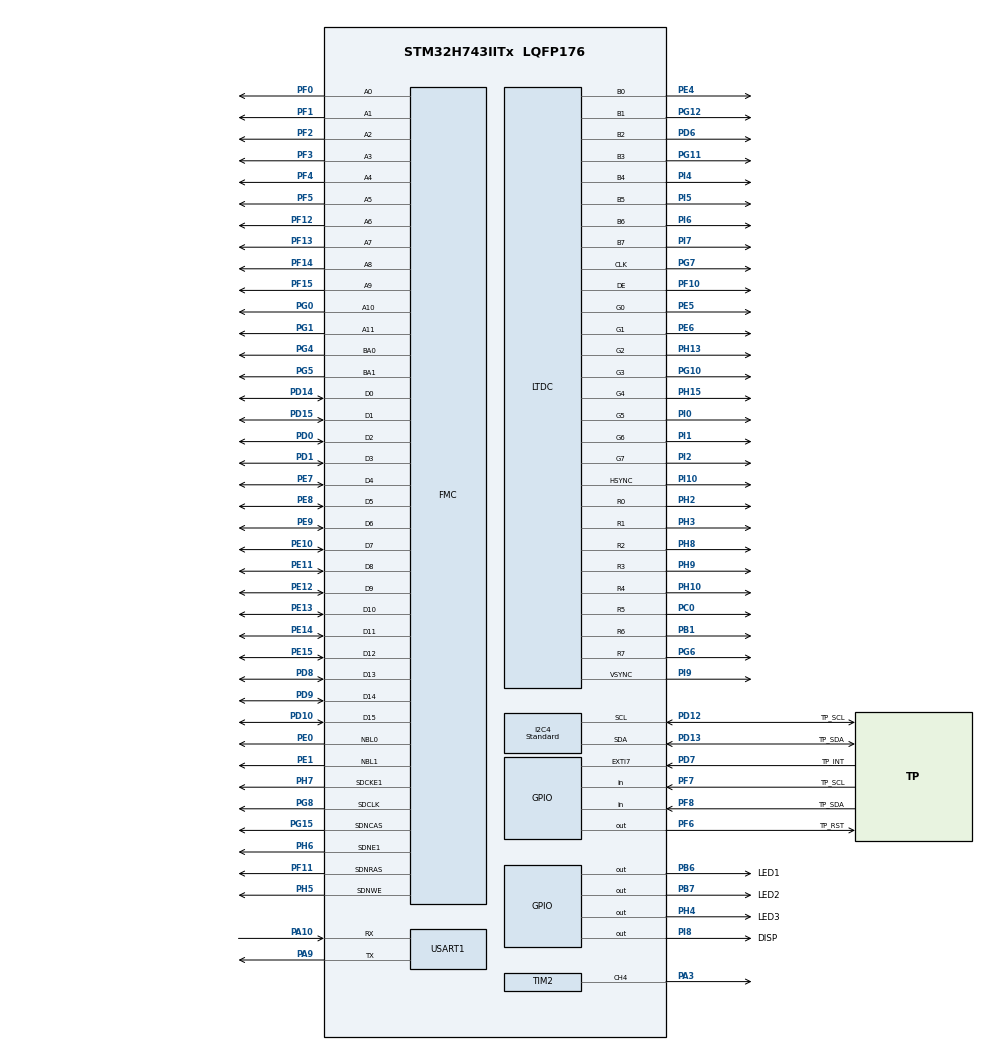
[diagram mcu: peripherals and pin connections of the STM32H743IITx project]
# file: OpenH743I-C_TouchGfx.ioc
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CORTEX_M7.BaseAddress-Cortex_Memory_Protection_Unit_Region0_Settings=0xD0000000
CORTEX_M7.CPU_DCache=Enabled
CORTEX_M7.CPU_ICache=Enabled
CORTEX_M7.Enable-Cortex_Memory_Protection_Unit_Region0_Settings=MPU_REGION_ENABLE
CORTEX_M7.MPU_Control=__NULL
CORTEX_M7.Size-Cortex_Memory_Protection_Unit_Region0_Settings=MPU_REGION_SIZE_16MB
CORTEX_M7.TypeExtField-Cortex_Memory_Protection_Unit_Region0_Settings=MPU_TEX_LEVEL1
DMA2D.ColorMode=DMA2D_OUTPUT_RGB565
FMC.CASLatency1=FMC_SDRAM_CAS_LATENCY_3
FMC.ExitSelfRefreshDelay1=7
FMC.LoadToActiveDelay1=2
FMC.RCDDelay1=2
FMC.RPDelay1=2
FMC.ReadPipeDelay1=FMC_SDRAM_RPIPE_DELAY_1
FMC.RowCycleDelay1=6
FMC.SDClockPeriod1=FMC_SDRAM_CLOCK_PERIOD_2
FMC.SelfRefreshTime1=4
FMC.WriteRecoveryTime1=2
FREERTOS.Tasks01=defaultTask,24,128,StartDefaultTask,Default,NULL,Dynamic,NULL,NULL;TouchGfxTask,24,2048,TouchGFX_Task,As weak,NULL,Dynamic,NULL,NULL
FREERTOS.configUSE_NEWLIB_REENTRANT=1
I2C4.CustomTiming=Disabled
I2C4.DualAddressMode=I2C_DUALADDRESS_DISABLE
I2C4.GeneralCallMode=I2C_GENERALCALL_DISABLE
I2C4.I2C_Speed_Mode=I2C_Standard
I2C4.NoStretchMode=I2C_NOSTRETCH_ENABLE
I2C4.Timing=0x00000E14
LTDC.ActiveW=800
LTDC.Alpha_L0=0xff
LTDC.FBStartAdress_L0=0xD0000000
LTDC.FBStartAdress_L1=0xD0200000
LTDC.HBP=46
LTDC.HFP=6
LTDC.HSync=30
LTDC.ImageHeight_L0=480
LTDC.ImageHeight_L1=480
LTDC.ImageWidth_L0=800
LTDC.Layers=0
LTDC.PixelFormat_L0=LTDC_PIXEL_FORMAT_RGB565
LTDC.VBP=23
LTDC.VFP=22
LTDC.VSync=10
LTDC.WindowX1_L0=800
LTDC.WindowX1_L1=800
LTDC.WindowY1_L0=480
LTDC.WindowY1_L1=480
Mcu.Family=STM32H7
Mcu.Name=STM32H743IITx
Mcu.Package=LQFP176
NVIC.DMA2D_IRQn=true\:5\:0\:false\:false\:true\:true\:true\:true\:true
NVIC.EXTI9_5_IRQn=true\:5\:0\:false\:false\:true\:true\:true\:true\:true
NVIC.LTDC_IRQn=true\:5\:0\:false\:false\:true\:true\:true\:true\:true
NVIC.PriorityGroup=NVIC_PRIORITYGROUP_4
NVIC.TIM1_UP_IRQn=true\:15\:0\:false\:false\:true\:false\:false\:true\:true
NVIC.TimeBase=TIM1_UP_IRQn
NVIC.TimeBaseIP=TIM1
PA10.Mode=Asynchronous
PA10.Signal=USART1_RX
PA3.Signal=S_TIM2_CH4
PA9.Mode=Asynchronous
PA9.Signal=USART1_TX
PB1.GPIO_Speed=GPIO_SPEED_FREQ_LOW
PB1.Mode=RGB888
PB1.Signal=LTDC_R6
PB6.GPIO_Label=LED1
PB6.Signal=GPIO_Output
PB7.GPIO_Label=LED2
PB7.Signal=GPIO_Output
PC0.Mode=RGB888
PC0.Signal=LTDC_R5
PD0.Signal=FMC_D2_DA2
PD1.Signal=FMC_D3_DA3
PD10.Signal=FMC_D15_DA15
PD12.GPIO_Label=TP_SCL
PD12.GPIO_Pu=GPIO_PULLUP
PD12.GPIO_PuPd=GPIO_PULLUP
PD12.GPIO_Speed=GPIO_SPEED_FREQ_HIGH
PD12.Mode=I2C
PD12.Signal=I2C4_SCL
PD13.GPIO_Label=TP_SDA
PD13.GPIO_Pu=GPIO_PULLUP
PD13.GPIO_PuPd=GPIO_PULLUP
PD13.GPIO_Speed=GPIO_SPEED_FREQ_HIGH
PD13.Mode=I2C
PD13.Signal=I2C4_SDA
PD14.Signal=FMC_D0_DA0
PD15.Signal=FMC_D1_DA1
PD6.Mode=RGB888
PD6.Signal=LTDC_B2
PD7.GPIO_Label=TP_INT
PD7.GPIO_PuPd=GPIO_PULLUP
PD7.Signal=GPXTI7
PD8.Signal=FMC_D13_DA13
PD9.Signal=FMC_D14_DA14
PE0.Signal=FMC_NBL0
PE1.Signal=FMC_NBL1
PE10.Signal=FMC_D7_DA7
PE11.Signal=FMC_D8_DA8
PE12.Signal=FMC_D9_DA9
PE13.Signal=FMC_D10_DA10
PE14.Signal=FMC_D11_DA11
PE15.Signal=FMC_D12_DA12
PE4.Mode=RGB888
PE4.Signal=LTDC_B0
PE5.Mode=RGB888
PE5.Signal=LTDC_G0
PE6.Mode=RGB888
PE6.Signal=LTDC_G1
PE7.Signal=FMC_D4_DA4
PE8.Signal=FMC_D5_DA5
PE9.Signal=FMC_D6_DA6
PF0.Signal=FMC_A0
PF1.Signal=FMC_A1
PF10.Mode=RGB888
PF10.Signal=LTDC_DE
PF11.Signal=FMC_SDNRAS
PF12.Signal=FMC_A6
PF13.Signal=FMC_A7
PF14.Signal=FMC_A8
PF15.Signal=FMC_A9
PF2.Signal=FMC_A2
PF3.Signal=FMC_A3
PF4.Signal=FMC_A4
PF5.Signal=FMC_A5
PF6.GPIO_Label=TP_RST
PF6.Signal=GPIO_Output
PF7.GPIO_Label=TP_SCL
PF7.Signal=GPIO_Input
PF8.GPIO_Label=TP_SDA
PF8.GPIO_PuPd=GPIO_PULLUP
PF8.Signal=GPIO_Input
PG0.Signal=FMC_A10
PG1.Signal=FMC_A11
PG10.Mode=RGB888
PG10.Signal=LTDC_G3
PG11.Mode=RGB888
PG11.Signal=LTDC_B3
PG12.Mode=RGB888
PG12.Signal=LTDC_B1
PG15.Signal=FMC_SDNCAS
PG4.Signal=FMC_A14_BA0
PG5.Signal=FMC_A15_BA1
PG6.Mode=RGB888
PG6.Signal=LTDC_R7
PG7.GPIO_Speed=GPIO_SPEED_FREQ_VERY_HIGH
PG7.Mode=RGB888
PG7.Signal=LTDC_CLK
PG8.Signal=FMC_SDCLK
PH0-OSC_IN\ (PH0).Mode=HSE-External-Oscillator
PH0-OSC_IN\ (PH0).Signal=RCC_OSC_IN
PH1-OSC_OUT\ (PH1).Mode=HSE-External-Oscillator
PH1-OSC_OUT\ (PH1).Signal=RCC_OSC_OUT
PH10.Mode=RGB888
PH10.Signal=LTDC_R4
PH13.Mode=RGB888
PH13.Signal=LTDC_G2
PH15.Mode=RGB888
PH15.Signal=LTDC_G4
PH2.Mode=RGB888
PH2.Signal=LTDC_R0
PH3.Mode=RGB888
PH3.Signal=LTDC_R1
PH4.GPIO_Label=LED3
PH4.Signal=GPIO_Output
PH5.Signal=FMC_SDNWE
PH6.Mode=SdramChipSelect2_1
PH6.Signal=FMC_SDNE1
PH7.Mode=SdramChipSelect2_1
PH7.Signal=FMC_SDCKE1
PH8.Mode=RGB888
PH8.Signal=LTDC_R2
PH9.Mode=RGB888
PH9.Signal=LTDC_R3
PI0.Mode=RGB888
PI0.Signal=LTDC_G5
PI1.Mode=RGB888
PI1.Signal=LTDC_G6
PI10.GPIO_Speed=GPIO_SPEED_FREQ_VERY_HIGH
PI10.Mode=RGB888
PI10.Signal=LTDC_HSYNC
PI2.Mode=RGB888
PI2.Signal=LTDC_G7
PI4.Mode=RGB888
PI4.Signal=LTDC_B4
PI5.Mode=RGB888
PI5.Signal=LTDC_B5
PI6.Mode=RGB888
PI6.Signal=LTDC_B6
PI7.Mode=RGB888
PI7.Signal=LTDC_B7
PI8.GPIO_Label=DISP
PI8.PinState=GPIO_PIN_SET
PI8.Signal=GPIO_Output
PI9.GPIO_Speed=GPIO_SPEED_FREQ_VERY_HIGH
PI9.Mode=RGB888
PI9.Signal=LTDC_VSYNC
ProjectManager.HeapSize=0x200
ProjectManager.StackSize=0x400
ProjectManager.TargetToolchain=STM32CubeIDE
RCC.ADCFreq_Value=100000000
RCC.APB1Freq_Value=50000000
RCC.APB2Freq_Value=100000000
RCC.APB3Freq_Value=100000000
RCC.APB4Freq_Value=100000000
RCC.CortexFreq_Value=400000000
RCC.D1PPRE=RCC_APB3_DIV2
RCC.D2PPRE1=RCC_APB1_DIV4
RCC.D2PPRE2=RCC_APB2_DIV2
RCC.D3PPRE=RCC_APB4_DIV2
RCC.DIVM1=4
RCC.DIVM2=4
RCC.DIVM3=4
RCC.DIVN1=400
RCC.DIVN2=100
RCC.DIVN3=96
RCC.DIVQ3=4
RCC.DIVR3=9
RCC.HCLKFreq_Value=200000000
RCC.HPRE=RCC_HCLK_DIV2
RCC.HSE_VALUE=8000000
RCC.I2C4CLockSelection=RCC_I2C4CLKSOURCE_CSI
RCC.PLLSourceVirtual=RCC_PLLSOURCE_HSE
RCC.PWR_Regulator_Voltage_Scale=PWR_REGULATOR_VOLTAGE_SCALE1
RCC.SYSCLKFreq_VALUE=400000000
RCC.SYSCLKSource=RCC_SYSCLKSOURCE_PLLCLK
RCC.USBFreq_Value=400000000
SH.FMC_A0.0=FMC_A0,12b-sda1
SH.FMC_A1.0=FMC_A1,12b-sda1
SH.FMC_A10.0=FMC_A10,12b-sda1
SH.FMC_A11.0=FMC_A11,12b-sda1
SH.FMC_A14_BA0.0=FMC_BA0,FourSdramBanks1
SH.FMC_A15_BA1.0=FMC_BA1,FourSdramBanks1
SH.FMC_A2.0=FMC_A2,12b-sda1
SH.FMC_A3.0=FMC_A3,12b-sda1
SH.FMC_A4.0=FMC_A4,12b-sda1
SH.FMC_A5.0=FMC_A5,12b-sda1
SH.FMC_A6.0=FMC_A6,12b-sda1
SH.FMC_A7.0=FMC_A7,12b-sda1
SH.FMC_A8.0=FMC_A8,12b-sda1
SH.FMC_A9.0=FMC_A9,12b-sda1
SH.FMC_D0_DA0.0=FMC_D0,sd-16b-d1
SH.FMC_D10_DA10.0=FMC_D10,sd-16b-d1
SH.FMC_D11_DA11.0=FMC_D11,sd-16b-d1
SH.FMC_D12_DA12.0=FMC_D12,sd-16b-d1
SH.FMC_D13_DA13.0=FMC_D13,sd-16b-d1
SH.FMC_D14_DA14.0=FMC_D14,sd-16b-d1
SH.FMC_D15_DA15.0=FMC_D15,sd-16b-d1
SH.FMC_D1_DA1.0=FMC_D1,sd-16b-d1
SH.FMC_D2_DA2.0=FMC_D2,sd-16b-d1
SH.FMC_D3_DA3.0=FMC_D3,sd-16b-d1
SH.FMC_D4_DA4.0=FMC_D4,sd-16b-d1
SH.FMC_D5_DA5.0=FMC_D5,sd-16b-d1
SH.FMC_D6_DA6.0=FMC_D6,sd-16b-d1
SH.FMC_D7_DA7.0=FMC_D7,sd-16b-d1
SH.FMC_D8_DA8.0=FMC_D8,sd-16b-d1
SH.FMC_D9_DA9.0=FMC_D9,sd-16b-d1
SH.FMC_NBL0.0=FMC_NBL0,Sd2ByteEnable1
SH.FMC_NBL1.0=FMC_NBL1,Sd2ByteEnable1
SH.FMC_SDCLK.0=FMC_SDCLK,12b-sda1
SH.FMC_SDNCAS.0=FMC_SDNCAS,12b-sda1
SH.FMC_SDNRAS.0=FMC_SDNRAS,12b-sda1
SH.FMC_SDNWE.0=FMC_SDNWE,12b-sda1
SH.S_TIM2_CH4.0=TIM2_CH4,PWM Generation4 CH4
STMicroelectronics.X-CUBE-TOUCHGFX.4.25.0.ApplicationCcGraphicsJjApplication=TouchGFXOoGenerator
STMicroelectronics.X-CUBE-TOUCHGFX.4.25.0.tgfx_address1=0xD0000000
STMicroelectronics.X-CUBE-TOUCHGFX.4.25.0.tgfx_display_interface=disp_ltdc
STMicroelectronics.X-CUBE-TOUCHGFX.4.25.0.tgfx_hardware_accelerator=dma_2d
STMicroelectronics.X-CUBE-TOUCHGFX.4.25.0.tgfx_location=Allocate
STMicroelectronics.X-CUBE-TOUCHGFX.4.25.0.tgfx_vsync=vsync_ltdc
STMicroelectronics.X-CUBE-TOUCHGFX.4.25.0_IsPackSelfContextualization=true
TIM2.AutoReloadPreload=TIM_AUTORELOAD_PRELOAD_ENABLE
TIM2.Channel-PWM\ Generation4\ CH4=TIM_CHANNEL_4
TIM2.Period=1000-1
TIM2.Prescaler=100-1
TIM2.Pulse-PWM\ Generation4\ CH4=500
USART1.VirtualMode-Asynchronous=VM_ASYNC
VP_CRC_VS_CRC.Mode=CRC_Activate
VP_DMA2D_VS_DMA2D.Mode=DMA2D_Activate
VP_FREERTOS_VS_CMSIS_V2.Mode=CMSIS_V2
VP_MEMORYMAP_VS_MEMORYMAP.Mode=CurAppReg
VP_STMicroelectronics.X-CUBE-TOUCHGFX_VS_GraphicsJjApplication_4.25.0.Mode=GraphicsJjApplication
VP_SYS_VS_tim1.Mode=TIM1
board=custom

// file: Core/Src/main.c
/* USER CODE BEGIN Header */
/**
 ******************************************************************************
 * @file           : main.c
 * @brief          : Main program body
 ******************************************************************************
 * @attention
 *
 * <h2><center>&copy; Copyright (c) 2020 STMicroelectronics.
 * All rights reserved.</center></h2>
 *
 * This software component is licensed by ST under BSD 3-Clause license,
 * the "License"; You may not use this file except in compliance with the
 * License. You may obtain a copy of the License at:
 *                        opensource.org/licenses/BSD-3-Clause
 *
 ******************************************************************************
 */
/* USER CODE END Header */
#include "main.h"
#include "cmsis_os.h"
#include "crc.h"
#include "dma2d.h"
#include "i2c.h"
#include "ltdc.h"
#include "memorymap.h"
#include "tim.h"
#include "usart.h"
#include "gpio.h"
#include "fmc.h"
#include "app_touchgfx.h"

/* USER CODE BEGIN Includes */
#include "BSP_SDRAM.h"
#include "BSP_RGB_LCD.h"
#include "GT811.h"

/* USER CODE END Includes */

/* USER CODE BEGIN PV */
uint16_t *FRAME_BUFFER = (uint16_t*) 0xD0000000;
/* USER CODE END PV */

void SystemClock_Config(void);
void MX_FREERTOS_Init(void);

int main(void)
{

  /* Enable the CPU Cache */

  /* Enable I-Cache---------------------------------------------------------*/
  SCB_EnableICache();

  /* Enable D-Cache---------------------------------------------------------*/
  SCB_EnableDCache();

  /* MCU Configuration--------------------------------------------------------*/

  /* Reset of all peripherals, Initializes the Flash interface and the Systick. */
  HAL_Init();

  /* Configure the system clock */
  SystemClock_Config();

  /* Initialize all configured peripherals */
  MX_GPIO_Init();
  MX_FMC_Init();
  MX_USART1_UART_Init();
  MX_LTDC_Init();
  MX_DMA2D_Init();
  MX_TIM2_Init();
  MX_CRC_Init();
  MX_I2C4_Init();
  MX_TouchGFX_Init();
  /* Call PreOsInit function */
  MX_TouchGFX_PreOSInit();

  /* Init scheduler */
  osKernelInitialize();

  /* Call init function for freertos objects (in cmsis_os2.c) */
  MX_FREERTOS_Init();

  /* Start scheduler */
  osKernelStart();

  /* We should never get here as control is now taken by the scheduler */

  /* Infinite loop */
  /* USER CODE BEGIN WHILE */
	BSP_LCD_Init();
	GT811_Init();
	BSP_LCD_Clear(LCD_COLOR_BLACK);

	while (1)
	{
    /* USER CODE END WHILE */

    /* USER CODE BEGIN 3 */
		HAL_GPIO_WritePin(LED1_GPIO_Port, LED1_Pin, GPIO_PIN_SET);
		HAL_Delay(1000);
		BSP_LCD_Clear(0xf000);
		HAL_GPIO_WritePin(LED2_GPIO_Port, LED2_Pin, GPIO_PIN_SET);
		HAL_Delay(1000);
		BSP_LCD_Clear(0x0f00);
		HAL_GPIO_WritePin(LED3_GPIO_Port, LED3_Pin, GPIO_PIN_SET);
		HAL_Delay(1000);
		BSP_LCD_Clear(0x00f0);
		HAL_GPIO_WritePin(LED1_GPIO_Port, LED1_Pin, GPIO_PIN_RESET);
		HAL_Delay(1000);
		BSP_LCD_Clear(0x000f);
		HAL_GPIO_WritePin(LED2_GPIO_Port, LED2_Pin, GPIO_PIN_RESET);
		HAL_Delay(1000);
		BSP_LCD_Clear(0xf00f);
		HAL_GPIO_WritePin(LED3_GPIO_Port, LED3_Pin, GPIO_PIN_RESET);
		HAL_Delay(1000);
	}
  /* USER CODE END 3 */
}

void SystemClock_Config(void)
{
  RCC_OscInitTypeDef RCC_OscInitStruct = {0};
  RCC_ClkInitTypeDef RCC_ClkInitStruct = {0};

  /** Supply configuration update enable
  */
  HAL_PWREx_ConfigSupply(PWR_LDO_SUPPLY);

  /** Configure the main internal regulator output voltage
  */
  __HAL_PWR_VOLTAGESCALING_CONFIG(PWR_REGULATOR_VOLTAGE_SCALE1);

  while(!__HAL_PWR_GET_FLAG(PWR_FLAG_VOSRDY)) {}

  /** Initializes the RCC Oscillators according to the specified parameters
  * in the RCC_OscInitTypeDef structure.
  */
  RCC_OscInitStruct.OscillatorType = RCC_OSCILLATORTYPE_CSI|RCC_OSCILLATORTYPE_HSE;
  RCC_OscInitStruct.HSEState = RCC_HSE_ON;
  RCC_OscInitStruct.CSIState = RCC_CSI_ON;
  RCC_OscInitStruct.CSICalibrationValue = RCC_CSICALIBRATION_DEFAULT;
  RCC_OscInitStruct.PLL.PLLState = RCC_PLL_ON;
  RCC_OscInitStruct.PLL.PLLSource = RCC_PLLSOURCE_HSE;
  RCC_OscInitStruct.PLL.PLLM = 4;
  RCC_OscInitStruct.PLL.PLLN = 400;
  RCC_OscInitStruct.PLL.PLLP = 2;
  RCC_OscInitStruct.PLL.PLLQ = 2;
  RCC_OscInitStruct.PLL.PLLR = 2;
  RCC_OscInitStruct.PLL.PLLRGE = RCC_PLL1VCIRANGE_1;
  RCC_OscInitStruct.PLL.PLLVCOSEL = RCC_PLL1VCOWIDE;
  RCC_OscInitStruct.PLL.PLLFRACN = 0;
  if (HAL_RCC_OscConfig(&RCC_OscInitStruct) != HAL_OK)
  {
    Error_Handler();
  }

  /** Initializes the CPU, AHB and APB buses clocks
  */
  RCC_ClkInitStruct.ClockType = RCC_CLOCKTYPE_HCLK|RCC_CLOCKTYPE_SYSCLK
                              |RCC_CLOCKTYPE_PCLK1|RCC_CLOCKTYPE_PCLK2
                              |RCC_CLOCKTYPE_D3PCLK1|RCC_CLOCKTYPE_D1PCLK1;
  RCC_ClkInitStruct.SYSCLKSource = RCC_SYSCLKSOURCE_PLLCLK;
  RCC_ClkInitStruct.SYSCLKDivider = RCC_SYSCLK_DIV1;
  RCC_ClkInitStruct.AHBCLKDivider = RCC_HCLK_DIV2;
  RCC_ClkInitStruct.APB3CLKDivider = RCC_APB3_DIV2;
  RCC_ClkInitStruct.APB1CLKDivider = RCC_APB1_DIV4;
  RCC_ClkInitStruct.APB2CLKDivider = RCC_APB2_DIV2;
  RCC_ClkInitStruct.APB4CLKDivider = RCC_APB4_DIV2;

  if (HAL_RCC_ClockConfig(&RCC_ClkInitStruct, FLASH_LATENCY_2) != HAL_OK)
  {
    Error_Handler();
  }
}

void HAL_TIM_PeriodElapsedCallback(TIM_HandleTypeDef *htim)
{
  if (htim->Instance == TIM1)
  {
    HAL_IncTick();
  }
}

void Error_Handler(void)
{
  /* USER CODE BEGIN Error_Handler_Debug */
	/* User can add his own implementation to report the HAL error return state */
	__disable_irq();
	while (1)
	{
		HAL_GPIO_WritePin(LED1_GPIO_Port, LED1_Pin, GPIO_PIN_SET);
		HAL_GPIO_WritePin(LED2_GPIO_Port, LED2_Pin, GPIO_PIN_SET);
		HAL_GPIO_WritePin(LED3_GPIO_Port, LED3_Pin, GPIO_PIN_SET);
	}
  /* USER CODE END Error_Handler_Debug */
}
